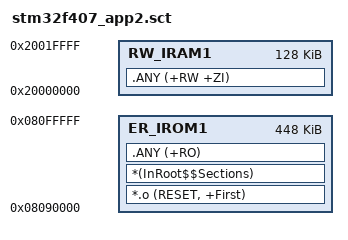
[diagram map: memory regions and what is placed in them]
; *************************************************************
; *** STM32F407 双APP分区链接脚本 - APP2配置 (448KB) ***
; *************************************************************
; 
; 内存分配:
;   0x08000000 - 0x0800FFFF (64KB)  : Bootloader
;   0x08010000 - 0x0808FFFF (512KB) : APP1区 (备份/稳定版本)
;   0x08090000 - 0x080FFFFF (448KB) : APP2区 (更新版本) ← 当前
;
; 编译方式:
;   1. 先编译APP1作为出厂固件
;   2. 使用此文件编译APP2生成OTA升级包
;   3. 将生成的.bin文件通过MQTT下发OTA升级
;   4. Bootloader会将固件从W25Q128搬运到0x08090000
;
; *************************************************************

LR_IROM1 0x08090000 0x00070000  {    ; APP2区: 起始0x08090000, 大小448KB
  ER_IROM1 0x08090000 0x00070000  {  ; 代码段
   *.o (RESET, +First)
   *(InRoot$$Sections)
   .ANY (+RO)
  }
  RW_IRAM1 0x20000000 0x00020000  {  ; RAM: 128KB (与APP1共享)
   .ANY (+RW +ZI)
  }
}
